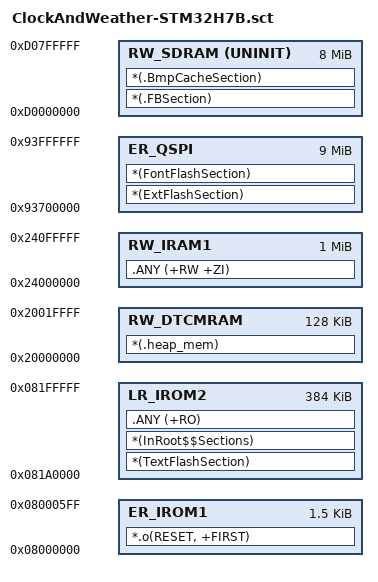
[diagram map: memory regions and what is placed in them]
; *************************************************************
; *** Scatter-Loading Description File generated by uVision ***
; *************************************************************

LR_IROM1 0x08000000 0x600 {    ; load region size_region

   ER_IROM1 0x08000000 0x600  {  ; load address = execution address
		*.o(RESET, +FIRST)
	}
     }
  
LR_IROM2 0x081A0000 0x60000  {    ; load region size_region
  LR_IROM2 0x081A0000  0x60000{
   *(TextFlashSection)
    *(InRoot$$Sections)
      .ANY (+RO)     
                }
                
     RW_DTCMRAM 0x20000000 0x20000  {  ; RW data
		*(.heap_mem) 
		}
     RW_IRAM1 0x24000000 0x100000  {     ; RW data
        .ANY (+RW +ZI)
                            }

  }
LR_QSPI 0x93700000 0x900000  {    ; load region size_region
  ER_QSPI 0x93700000 0x900000 {         
  *(ExtFlashSection)
    *(FontFlashSection)           
              }
    RW_SDRAM 0xD0000000 UNINIT 0x800000  {  ; RW data
   *(.FBSection)
   *(.BmpCacheSection)
   
}
}


